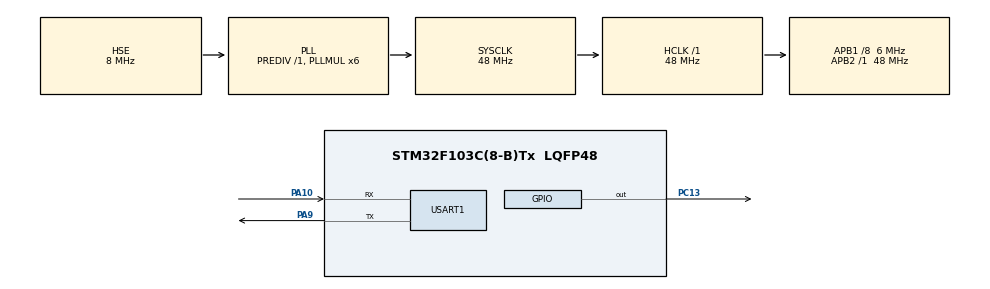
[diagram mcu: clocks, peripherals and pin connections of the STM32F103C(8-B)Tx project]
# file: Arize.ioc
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Mcu.Family=STM32F1
Mcu.Name=STM32F103C(8-B)Tx
Mcu.Package=LQFP48
NVIC.PriorityGroup=NVIC_PRIORITYGROUP_4
NVIC.TIM1_UP_IRQn=true\:15\:0\:false\:false\:true\:false\:true
NVIC.TimeBase=TIM1_UP_IRQn
NVIC.TimeBaseIP=TIM1
PA0-WKUP.Mode=SYS_WakeUp0
PA0-WKUP.Signal=SYS_WKUP
PA10.Mode=Asynchronous
PA10.Signal=USART1_RX
PA9.Mode=Asynchronous
PA9.Signal=USART1_TX
PC13-TAMPER-RTC.GPIO_ModeDefaultOutputPP=GPIO_MODE_OUTPUT_PP
PC13-TAMPER-RTC.GPIO_PuPd=GPIO_NOPULL
PC13-TAMPER-RTC.GPIO_Speed=GPIO_SPEED_FREQ_MEDIUM
PC13-TAMPER-RTC.PinState=GPIO_PIN_RESET
PC13-TAMPER-RTC.Signal=GPIO_Output
PC14-OSC32_IN.Mode=LSE-External-Oscillator
PC14-OSC32_IN.Signal=RCC_OSC32_IN
PC15-OSC32_OUT.Mode=LSE-External-Oscillator
PC15-OSC32_OUT.Signal=RCC_OSC32_OUT
PD0-OSC_IN.Mode=HSE-External-Oscillator
PD0-OSC_IN.Signal=RCC_OSC_IN
PD1-OSC_OUT.Mode=HSE-External-Oscillator
PD1-OSC_OUT.Signal=RCC_OSC_OUT
ProjectManager.HeapSize=0x200
ProjectManager.StackSize=0x400
ProjectManager.TargetToolchain=MDK-ARM V5
RCC.AHBFreq_Value=48000000
RCC.APB1CLKDivider=RCC_HCLK_DIV8
RCC.APB1Freq_Value=6000000
RCC.APB1TimFreq_Value=12000000
RCC.APB2Freq_Value=48000000
RCC.APB2TimFreq_Value=48000000
RCC.HCLKFreq_Value=48000000
RCC.PLLMUL=RCC_PLL_MUL6
RCC.PLLSourceVirtual=RCC_PLLSOURCE_HSE
RCC.SYSCLKFreq_VALUE=48000000
RCC.SYSCLKSource=RCC_SYSCLKSOURCE_PLLCLK
RCC.USBFreq_Value=48000000
USART1.VirtualMode=VM_ASYNC
VP_SYS_VS_ND.Mode=No_Debug
VP_SYS_VS_tim1.Mode=TIM1
VP_TIM2_VS_ClockSourceINT.Mode=Internal
VP_TIM2_VS_ClockSourceITR.Mode=TriggerSource_ITR0
VP_WWDG_VS_WWDG.Mode=WWDG_Activate
board=custom

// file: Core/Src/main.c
/* USER CODE BEGIN Header */
/**
  ******************************************************************************
  * @file           : main.c
  * @brief          : Main program body
  ******************************************************************************
  * @attention
  *
  * <h2><center>&copy; Copyright (c) 2022 STMicroelectronics.
  * All rights reserved.</center></h2>
  *
  * This software component is licensed by ST under Ultimate Liberty license
  * SLA0044, the "License"; You may not use this file except in compliance with
  * the License. You may obtain a copy of the License at:
  *                             www.st.com/SLA0044
  *
  ******************************************************************************
  */
/* USER CODE END Header */
#include "main.h"
#include "tim.h"
#include "usart.h"
#include "wwdg.h"
#include "gpio.h"

void SystemClock_Config(void);

/* USER CODE BEGIN 0 */

static int fac_us=0;
//delay nus
void delay_us(int nus)
{
    int ticks;
    int told,tnow,tcnt=0;
    int reload=SysTick->LOAD;
    ticks=nus*fac_us;
    told=SysTick->VAL;
    while(1)
    {
        tnow=SysTick->VAL;
        if(tnow!=told)
        {
            if(tnow<told)tcnt+=told-tnow;
            else tcnt+=reload-tnow+told;
            told=tnow;
            if(tcnt>=ticks)break;
        }
    };
}

//delay nms
void delay_ms(int nms)
{
    int i;
    for(i=0;i<nms;i++) delay_us(1000);
}

/* USER CODE END 0 */

int main(void)
{

  /* MCU Configuration--------------------------------------------------------*/

  /* Reset of all peripherals, Initializes the Flash interface and the Systick. */
  HAL_Init();

  /* Configure the system clock */
  SystemClock_Config();

  /* Initialize all configured peripherals */
  MX_GPIO_Init();
  MX_TIM2_Init();
  MX_WWDG_Init();
  MX_USART1_UART_Init();

  /* Infinite loop */
  while (1)
  {

    /* USER CODE BEGIN 3 */
    HAL_GPIO_WritePin(GPIOC, GPIO_PIN_13, GPIO_PIN_SET);

  }
  /* USER CODE END 3 */
}

void SystemClock_Config(void)
{
  RCC_OscInitTypeDef RCC_OscInitStruct = {0};
  RCC_ClkInitTypeDef RCC_ClkInitStruct = {0};

  /** Initializes the RCC Oscillators according to the specified parameters
  * in the RCC_OscInitTypeDef structure.
  */
  RCC_OscInitStruct.OscillatorType = RCC_OSCILLATORTYPE_HSE;
  RCC_OscInitStruct.HSEState = RCC_HSE_ON;
  RCC_OscInitStruct.HSEPredivValue = RCC_HSE_PREDIV_DIV1;
  RCC_OscInitStruct.HSIState = RCC_HSI_ON;
  RCC_OscInitStruct.PLL.PLLState = RCC_PLL_ON;
  RCC_OscInitStruct.PLL.PLLSource = RCC_PLLSOURCE_HSE;
  RCC_OscInitStruct.PLL.PLLMUL = RCC_PLL_MUL6;
  if (HAL_RCC_OscConfig(&RCC_OscInitStruct) != HAL_OK)
  {
    Error_Handler();
  }
  /** Initializes the CPU, AHB and APB buses clocks
  */
  RCC_ClkInitStruct.ClockType = RCC_CLOCKTYPE_HCLK|RCC_CLOCKTYPE_SYSCLK
                              |RCC_CLOCKTYPE_PCLK1|RCC_CLOCKTYPE_PCLK2;
  RCC_ClkInitStruct.SYSCLKSource = RCC_SYSCLKSOURCE_PLLCLK;
  RCC_ClkInitStruct.AHBCLKDivider = RCC_SYSCLK_DIV1;
  RCC_ClkInitStruct.APB1CLKDivider = RCC_HCLK_DIV8;
  RCC_ClkInitStruct.APB2CLKDivider = RCC_HCLK_DIV1;

  if (HAL_RCC_ClockConfig(&RCC_ClkInitStruct, FLASH_LATENCY_1) != HAL_OK)
  {
    Error_Handler();
  }
}

void HAL_TIM_PeriodElapsedCallback(TIM_HandleTypeDef *htim)
{
  if (htim->Instance == TIM1) {
    HAL_IncTick();
  }
}

void Error_Handler(void)
{
  __disable_irq();
  while (1)
  {
  }
}

/************************ (C) COPYRIGHT STMicroelectronics *****END OF FILE****/
